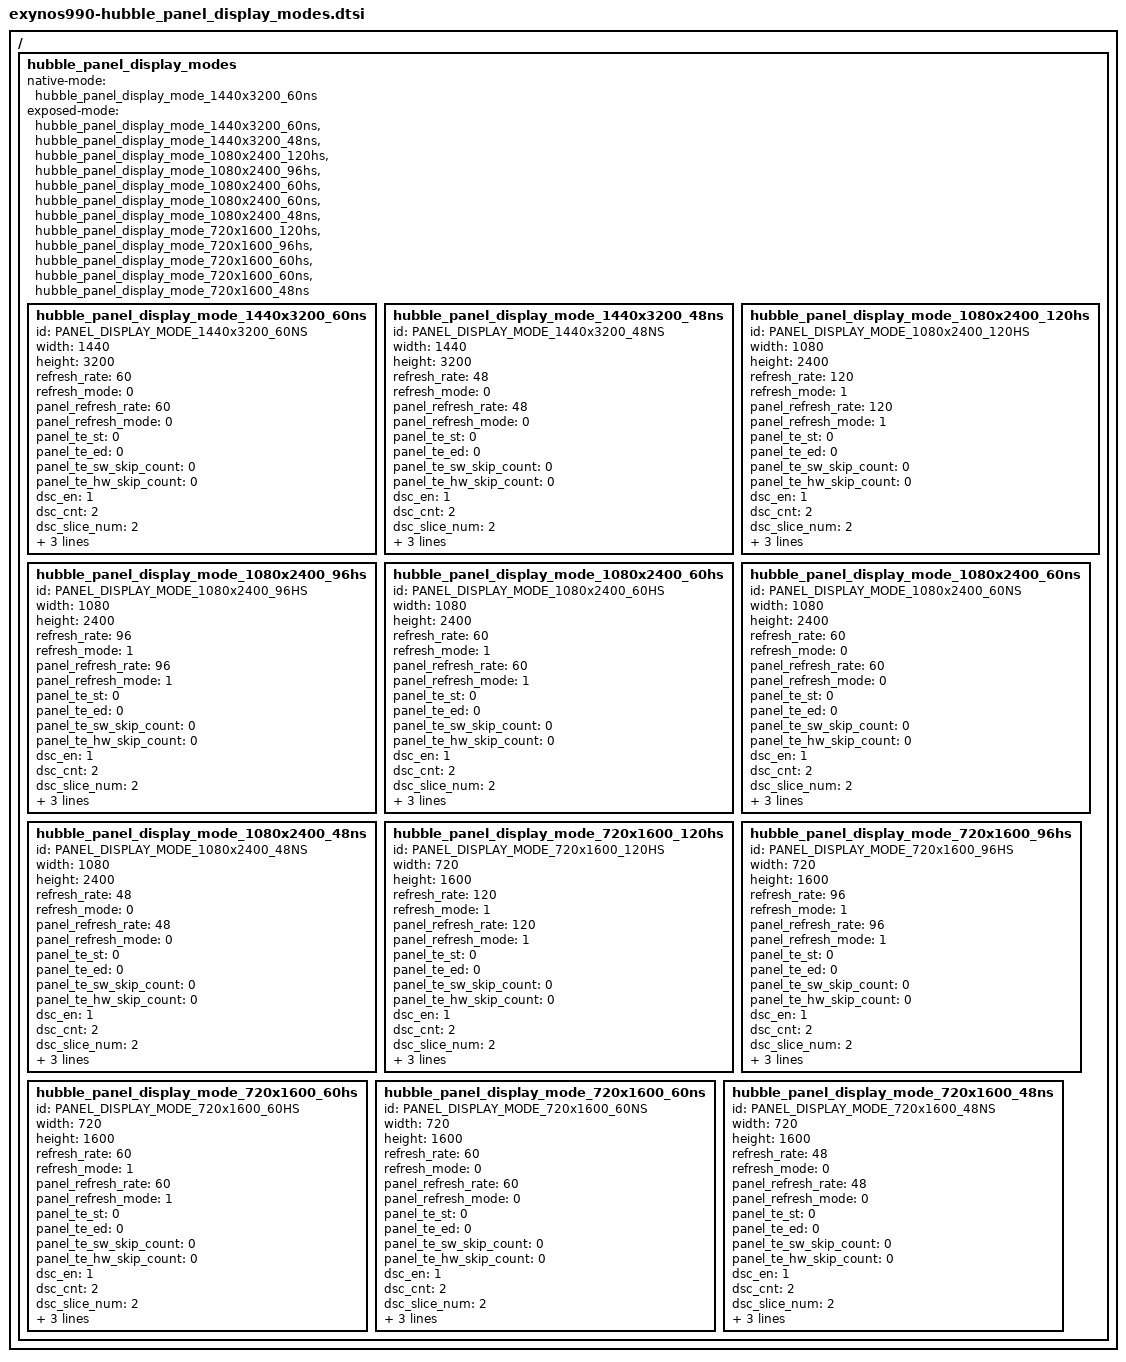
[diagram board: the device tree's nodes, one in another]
/*
 * SAMSUNG LCD Panel Device Tree Source
 *
 * Copyright (c) 2020 Samsung Electronics Co., Ltd.
 *		http://www.samsung.com
 *
 * This program is free software; you can redistribute it and/or modify
 * it under the terms of the GNU General Public License version 2 as
 * published by the Free Software Foundation.
 */

#include <dt-bindings/display/panel-display.h>

/ {
	fragment@panel_display_mode {
		target-path = "/";
		__overlay__ {
			hubble_panel_display_modes:
			hubble_panel_display_modes {
				native-mode = <&hubble_panel_display_mode_1440x3200_60ns>;
				exposed-mode = <
					&hubble_panel_display_mode_1440x3200_60ns
					&hubble_panel_display_mode_1440x3200_48ns
					&hubble_panel_display_mode_1080x2400_120hs
					&hubble_panel_display_mode_1080x2400_96hs
					&hubble_panel_display_mode_1080x2400_60hs
					&hubble_panel_display_mode_1080x2400_60ns
					&hubble_panel_display_mode_1080x2400_48ns
					&hubble_panel_display_mode_720x1600_120hs
					&hubble_panel_display_mode_720x1600_96hs
					&hubble_panel_display_mode_720x1600_60hs
					&hubble_panel_display_mode_720x1600_60ns
					&hubble_panel_display_mode_720x1600_48ns
				>;

				/* wqhd */
				hubble_panel_display_mode_1440x3200_60ns:
				hubble_panel_display_mode_1440x3200_60ns {
					id = PANEL_DISPLAY_MODE_1440x3200_60NS;
					width = <1440>;
					height = <3200>;
					/* timing parameters */
					refresh_rate = <60>;			/* logical refresh rate */
					refresh_mode = <0>;				/* 0:NS, 1:HS */
					panel_refresh_rate = <60>;		/* panel internal refresh rate */
					panel_refresh_mode = <0>;		/* 0:NS, 1:HS */
					panel_te_st = <0>;				/* te rising */
					panel_te_ed = <0>;				/* te falling */
					panel_te_sw_skip_count = <0>;	/* s/w te modulation */
					panel_te_hw_skip_count = <0>;	/* h/w te modulation */
					/* dsc parameters */
					dsc_en = <1>;			/* 0:Disable, 1:Enable */
					dsc_cnt = <2>;			/* used DSC count */
					dsc_slice_num = <2>;	/* count of dsc slice */
					dsc_slice_w = <720>;	/* width of dsc slice */
					dsc_slice_h = <40>;	/* height of dsc slice */
					/* dsi parameters */
					cmd_lp_ref = <7790>;
				};

				hubble_panel_display_mode_1440x3200_48ns:
				hubble_panel_display_mode_1440x3200_48ns {
					id = PANEL_DISPLAY_MODE_1440x3200_48NS;
					width = <1440>;
					height = <3200>;
					/* timing parameters */
					refresh_rate = <48>;			/* logical refresh rate */
					refresh_mode = <0>;				/* 0:NS, 1:HS */
					panel_refresh_rate = <48>;		/* panel internal refresh rate */
					panel_refresh_mode = <0>;		/* 0:NS, 1:HS */
					panel_te_st = <0>;				/* te rising */
					panel_te_ed = <0>;				/* te falling */
					panel_te_sw_skip_count = <0>;	/* s/w te modulation */
					panel_te_hw_skip_count = <0>;	/* h/w te modulation */
					/* dsc parameters */
					dsc_en = <1>;			/* 0:Disable, 1:Enable */
					dsc_cnt = <2>;			/* used DSC count */
					dsc_slice_num = <2>;	/* count of dsc slice */
					dsc_slice_w = <720>;	/* width of dsc slice */
					dsc_slice_h = <40>;	/* height of dsc slice */
					/* dsi parameters */
					cmd_lp_ref = <7790>;
				};

				/* fhd */
				hubble_panel_display_mode_1080x2400_120hs:
				hubble_panel_display_mode_1080x2400_120hs {
					id = PANEL_DISPLAY_MODE_1080x2400_120HS;
					width = <1080>;
					height = <2400>;
					/* timing parameters */
					refresh_rate = <120>;			/* logical refresh rate */
					refresh_mode = <1>;				/* 0:NS, 1:HS */
					panel_refresh_rate = <120>;		/* panel internal refresh rate */
					panel_refresh_mode = <1>;		/* 0:NS, 1:HS */
					panel_te_st = <0>;				/* te rising */
					panel_te_ed = <0>;				/* te falling */
					panel_te_sw_skip_count = <0>;	/* s/w te modulation */
					panel_te_hw_skip_count = <0>;	/* h/w te modulation */
					/* dsc parameters */
					dsc_en = <1>;			/* 0:Disable, 1:Enable */
					dsc_cnt = <2>;			/* used DSC count */
					dsc_slice_num = <2>;	/* count of dsc slice */
					dsc_slice_w = <540>;	/* width of dsc slice */
					dsc_slice_h = <40>;	/* height of dsc slice */
					/* dsi parameters */
					cmd_lp_ref = <10317>;
				};

				hubble_panel_display_mode_1080x2400_96hs:
				hubble_panel_display_mode_1080x2400_96hs {
					id = PANEL_DISPLAY_MODE_1080x2400_96HS;
					width = <1080>;
					height = <2400>;
					/* timing parameters */
					refresh_rate = <96>;			/* logical refresh rate */
					refresh_mode = <1>;				/* 0:NS, 1:HS */
					panel_refresh_rate = <96>;		/* panel internal refresh rate */
					panel_refresh_mode = <1>;		/* 0:NS, 1:HS */
					panel_te_st = <0>;				/* te rising */
					panel_te_ed = <0>;				/* te falling */
					panel_te_sw_skip_count = <0>;	/* s/w te modulation */
					panel_te_hw_skip_count = <0>;	/* h/w te modulation */
					/* dsc parameters */
					dsc_en = <1>;			/* 0:Disable, 1:Enable */
					dsc_cnt = <2>;			/* used DSC count */
					dsc_slice_num = <2>;	/* count of dsc slice */
					dsc_slice_w = <540>;	/* width of dsc slice */
					dsc_slice_h = <40>;	/* height of dsc slice */
					/* dsi parameters */
					cmd_lp_ref = <10317>;
				};

				hubble_panel_display_mode_1080x2400_60hs:
				hubble_panel_display_mode_1080x2400_60hs {
					id = PANEL_DISPLAY_MODE_1080x2400_60HS;
					width = <1080>;
					height = <2400>;
					/* timing parameters */
					refresh_rate = <60>;			/* logical refresh rate */
					refresh_mode = <1>;				/* 0:NS, 1:HS */
					panel_refresh_rate = <60>;		/* panel internal refresh rate */
					panel_refresh_mode = <1>;		/* 0:NS, 1:HS */
					panel_te_st = <0>;				/* te rising */
					panel_te_ed = <0>;				/* te falling */
					panel_te_sw_skip_count = <0>;	/* s/w te modulation */
					panel_te_hw_skip_count = <0>;	/* h/w te modulation */
					/* dsc parameters */
					dsc_en = <1>;			/* 0:Disable, 1:Enable */
					dsc_cnt = <2>;			/* used DSC count */
					dsc_slice_num = <2>;	/* count of dsc slice */
					dsc_slice_w = <540>;	/* width of dsc slice */
					dsc_slice_h = <40>;	/* height of dsc slice */
					/* dsi parameters */
					cmd_lp_ref = <10317>;
				};

				hubble_panel_display_mode_1080x2400_60ns:
				hubble_panel_display_mode_1080x2400_60ns {
					id = PANEL_DISPLAY_MODE_1080x2400_60NS;
					width = <1080>;
					height = <2400>;
					/* timing parameters */
					refresh_rate = <60>;			/* logical refresh rate */
					refresh_mode = <0>;				/* 0:NS, 1:HS */
					panel_refresh_rate = <60>;		/* panel internal refresh rate */
					panel_refresh_mode = <0>;		/* 0:NS, 1:HS */
					panel_te_st = <0>;				/* te rising */
					panel_te_ed = <0>;				/* te falling */
					panel_te_sw_skip_count = <0>;	/* s/w te modulation */
					panel_te_hw_skip_count = <0>;	/* h/w te modulation */
					/* dsc parameters */
					dsc_en = <1>;			/* 0:Disable, 1:Enable */
					dsc_cnt = <2>;			/* used DSC count */
					dsc_slice_num = <2>;	/* count of dsc slice */
					dsc_slice_w = <540>;	/* width of dsc slice */
					dsc_slice_h = <40>;	/* height of dsc slice */
					/* dsi parameters */
					cmd_lp_ref = <10317>;
				};

				hubble_panel_display_mode_1080x2400_48ns:
				hubble_panel_display_mode_1080x2400_48ns {
					id = PANEL_DISPLAY_MODE_1080x2400_48NS;
					width = <1080>;
					height = <2400>;
					/* timing parameters */
					refresh_rate = <48>;			/* logical refresh rate */
					refresh_mode = <0>;				/* 0:NS, 1:HS */
					panel_refresh_rate = <48>;		/* panel internal refresh rate */
					panel_refresh_mode = <0>;		/* 0:NS, 1:HS */
					panel_te_st = <0>;				/* te rising */
					panel_te_ed = <0>;				/* te falling */
					panel_te_sw_skip_count = <0>;	/* s/w te modulation */
					panel_te_hw_skip_count = <0>;	/* h/w te modulation */
					/* dsc parameters */
					dsc_en = <1>;			/* 0:Disable, 1:Enable */
					dsc_cnt = <2>;			/* used DSC count */
					dsc_slice_num = <2>;	/* count of dsc slice */
					dsc_slice_w = <540>;	/* width of dsc slice */
					dsc_slice_h = <40>;	/* height of dsc slice */
					/* dsi parameters */
					cmd_lp_ref = <10317>;
				};

				/* hd */
				hubble_panel_display_mode_720x1600_120hs:
				hubble_panel_display_mode_720x1600_120hs {
					id = PANEL_DISPLAY_MODE_720x1600_120HS;
					width = <720>;
					height = <1600>;
					/* timing parameters */
					refresh_rate = <120>;			/* logical refresh rate */
					refresh_mode = <1>;				/* 0:NS, 1:HS */
					panel_refresh_rate = <120>;		/* panel internal refresh rate */
					panel_refresh_mode = <1>;		/* 0:NS, 1:HS */
					panel_te_st = <0>;				/* te rising */
					panel_te_ed = <0>;				/* te falling */
					panel_te_sw_skip_count = <0>;	/* s/w te modulation */
					panel_te_hw_skip_count = <0>;	/* h/w te modulation */
					/* dsc parameters */
					dsc_en = <1>;			/* 0:Disable, 1:Enable */
					dsc_cnt = <2>;			/* used DSC count */
					dsc_slice_num = <2>;	/* count of dsc slice */
					dsc_slice_w = <360>;	/* width of dsc slice */
					dsc_slice_h = <80>;	/* height of dsc slice */
					/* dsi parameters */
					cmd_lp_ref = <11404>;
				};

				hubble_panel_display_mode_720x1600_96hs:
				hubble_panel_display_mode_720x1600_96hs {
					id = PANEL_DISPLAY_MODE_720x1600_96HS;
					width = <720>;
					height = <1600>;
					/* timing parameters */
					refresh_rate = <96>;			/* logical refresh rate */
					refresh_mode = <1>;				/* 0:NS, 1:HS */
					panel_refresh_rate = <96>;		/* panel internal refresh rate */
					panel_refresh_mode = <1>;		/* 0:NS, 1:HS */
					panel_te_st = <0>;				/* te rising */
					panel_te_ed = <0>;				/* te falling */
					panel_te_sw_skip_count = <0>;	/* s/w te modulation */
					panel_te_hw_skip_count = <0>;	/* h/w te modulation */
					/* dsc parameters */
					dsc_en = <1>;			/* 0:Disable, 1:Enable */
					dsc_cnt = <2>;			/* used DSC count */
					dsc_slice_num = <2>;	/* count of dsc slice */
					dsc_slice_w = <360>;	/* width of dsc slice */
					dsc_slice_h = <80>;	/* height of dsc slice */
					/* dsi parameters */
					cmd_lp_ref = <11404>;
				};

				hubble_panel_display_mode_720x1600_60hs:
				hubble_panel_display_mode_720x1600_60hs {
					id = PANEL_DISPLAY_MODE_720x1600_60HS;
					width = <720>;
					height = <1600>;
					/* timing parameters */
					refresh_rate = <60>;			/* logical refresh rate */
					refresh_mode = <1>;				/* 0:NS, 1:HS */
					panel_refresh_rate = <60>;		/* panel internal refresh rate */
					panel_refresh_mode = <1>;		/* 0:NS, 1:HS */
					panel_te_st = <0>;				/* te rising */
					panel_te_ed = <0>;				/* te falling */
					panel_te_sw_skip_count = <0>;	/* s/w te modulation */
					panel_te_hw_skip_count = <0>;	/* h/w te modulation */
					/* dsc parameters */
					dsc_en = <1>;			/* 0:Disable, 1:Enable */
					dsc_cnt = <2>;			/* used DSC count */
					dsc_slice_num = <2>;	/* count of dsc slice */
					dsc_slice_w = <360>;	/* width of dsc slice */
					dsc_slice_h = <80>;	/* height of dsc slice */
					/* dsi parameters */
					cmd_lp_ref = <11404>;
				};

				hubble_panel_display_mode_720x1600_60ns:
				hubble_panel_display_mode_720x1600_60ns {
					id = PANEL_DISPLAY_MODE_720x1600_60NS;
					width = <720>;
					height = <1600>;
					/* timing parameters */
					refresh_rate = <60>;			/* logical refresh rate */
					refresh_mode = <0>;				/* 0:NS, 1:HS */
					panel_refresh_rate = <60>;		/* panel internal refresh rate */
					panel_refresh_mode = <0>;		/* 0:NS, 1:HS */
					panel_te_st = <0>;				/* te rising */
					panel_te_ed = <0>;				/* te falling */
					panel_te_sw_skip_count = <0>;	/* s/w te modulation */
					panel_te_hw_skip_count = <0>;	/* h/w te modulation */
					/* dsc parameters */
					dsc_en = <1>;			/* 0:Disable, 1:Enable */
					dsc_cnt = <2>;			/* used DSC count */
					dsc_slice_num = <2>;	/* count of dsc slice */
					dsc_slice_w = <360>;	/* width of dsc slice */
					dsc_slice_h = <80>;	/* height of dsc slice */
					/* dsi parameters */
					cmd_lp_ref = <11404>;
				};

				hubble_panel_display_mode_720x1600_48ns:
				hubble_panel_display_mode_720x1600_48ns {
					id = PANEL_DISPLAY_MODE_720x1600_48NS;
					width = <720>;
					height = <1600>;
					/* timing parameters */
					refresh_rate = <48>;			/* logical refresh rate */
					refresh_mode = <0>;				/* 0:NS, 1:HS */
					panel_refresh_rate = <48>;		/* panel internal refresh rate */
					panel_refresh_mode = <0>;		/* 0:NS, 1:HS */
					panel_te_st = <0>;				/* te rising */
					panel_te_ed = <0>;				/* te falling */
					panel_te_sw_skip_count = <0>;	/* s/w te modulation */
					panel_te_hw_skip_count = <0>;	/* h/w te modulation */
					/* dsc parameters */
					dsc_en = <1>;			/* 0:Disable, 1:Enable */
					dsc_cnt = <2>;			/* used DSC count */
					dsc_slice_num = <2>;	/* count of dsc slice */
					dsc_slice_w = <360>;	/* width of dsc slice */
					dsc_slice_h = <80>;	/* height of dsc slice */
					/* dsi parameters */
					cmd_lp_ref = <11404>;
				};
			};
		};
	};
};
